# CPU_SCS register map
Vendor: Texas Instruments
Peripheral module from a debugger description file (folder CC26x0R2F).
Registers are 32-bit, read-write, reset 0x0 unless marked. A register's access mark holds for its fields unless they carry their own. Offsets are as the file gives them; lines under a group give offsets from that group; [hi:lo] are bit positions; {n}, {i} and the like mark numbered series; 'fields as' and 'values as' point back to an identical list; <NAME> marks a mode.

## CPU_SCS — Cortex-M's System Control Space (SCS)
0x04 ICTR ro reset 0x1 — Interrupt Control Type Read this register to see the number of interrupt lines that the NVIC supports.
  [2:0] INTLINESNUM — Total number of interrupt lines in groups of 32. 0: 0...32 1: 33...64 2: 65...96 3: 97...128 4: 129...160 5: 161...192 6: 193...224 7: 225...256
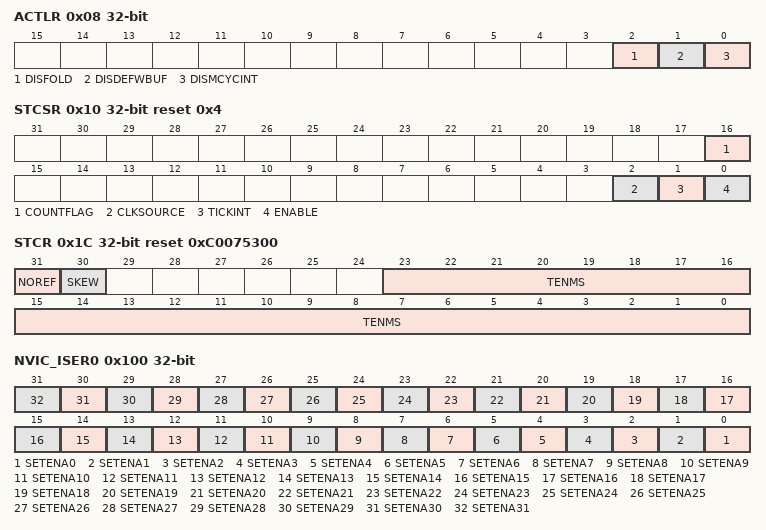
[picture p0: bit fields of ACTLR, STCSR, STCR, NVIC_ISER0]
0x08 ACTLR — Auxiliary Control This register is used to disable certain aspects of functionality within the processor
  [2] DISFOLD — Disables folding of IT instruction.
  [1] DISDEFWBUF — Disables write buffer use during default memory map accesses. This causes all bus faults to be precise bus faults but decreases the performance of the processor because the stores to memory have to complete before the next instruction can be executed.
  [0] DISMCYCINT — Disables interruption of multi-cycle instructions. This increases the interrupt latency of the processor becuase LDM/STM completes before interrupt stacking occurs.
0x10 STCSR access per field reset 0x4 — SysTick Control and Status This register enables the SysTick features and returns status flags related to SysTick.
  [16] COUNTFLAG ro — Returns 1 if timer counted to 0 since last time this was read. Clears on read by application of any part of the SysTick Control and Status Register. If read by the debugger using the DAP, this bit is cleared on read-only if the MasterType bit in the **AHB-AP** Control Register is set to 0. Otherwise, COUNTFLAG is not changed by the debugger read.
  [2] CLKSOURCE ro — Clock source: 0: External reference clock. 1: Core clock External clock is not available in this device. Writes to this field will be ignored.
  [1] TICKINT rw — 0: Counting down to zero does not pend the SysTick handler. Software can use COUNTFLAG to determine if the SysTick handler has ever counted to zero. 1: Counting down to zero pends the SysTick handler.
  [0] ENABLE rw — Enable SysTick counter 0: Counter disabled 1: Counter operates in a multi-shot way. That is, counter loads with the Reload value STRVR.RELOAD and then begins counting down. On reaching 0, it sets COUNTFLAG to 1 and optionally pends the SysTick handler, based on TICKINT. It then loads STRVR.RELOAD again, and begins counting.
0x14 STRVR — SysTick Reload Value This register is used to specify the start value to load into the current value register STCVR.CURRENT when the counter reaches 0. It can be any value between 1 and 0x00FFFFFF. A start value of 0 is possible, but has no effect because the SysTick interrupt and STCSR.COUNTFLAG are activated when counting from 1 to 0.
  [23:0] RELOAD — Value to load into the SysTick Current Value Register STCVR.CURRENT when the counter reaches 0.
0x18 STCVR — SysTick Current Value Read from this register returns the current value of SysTick counter. Writing to this register resets the SysTick counter (as well as STCSR.COUNTFLAG).
  [23:0] CURRENT — Current value at the time the register is accessed. No read-modify-write protection is provided, so change with care. Writing to it with any value clears the register to 0. Clearing this register also clears STCSR.COUNTFLAG.
0x1C STCR ro reset 0xC0075300 — SysTick Calibration Value Used to enable software to scale to any required speed using divide and multiply.
  [31] NOREF — Reads as one. Indicates that no separate reference clock is provided.
  [30] SKEW — Reads as one. The calibration value is not exactly 10ms because of clock frequency. This could affect its suitability as a software real time clock.
  [23:0] TENMS — An optional Reload value to be used for 10ms (100Hz) timing, subject to system clock skew errors. The value read is valid only when core clock is at 48MHz.
0x100 NVIC_ISER0 — Irq 0 to 31 Set Enable This register is used to enable interrupts and determine which interrupts are currently enabled.
  [n] SETENA{n} (n=0..31) — Writing 0 to this bit has no effect, writing 1 to this bit enables the interrupt number {n} (See EVENT:CPUIRQSEL{n}.EV for details). Reading the bit returns its current enable state.
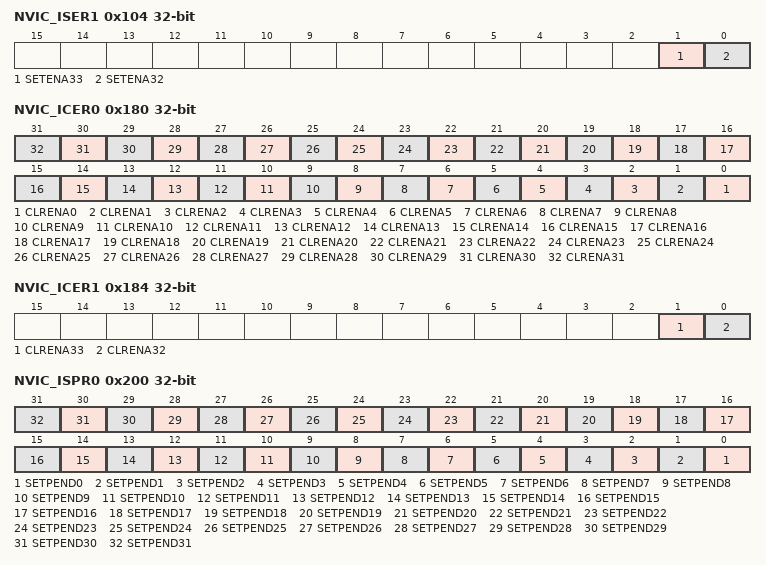
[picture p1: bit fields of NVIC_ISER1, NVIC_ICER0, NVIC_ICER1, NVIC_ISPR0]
0x104 NVIC_ISER1 — Irq 32 to 63 Set Enable This register is used to enable interrupts and determine which interrupts are currently enabled.
  [1] SETENA33 — Writing 0 to this bit has no effect, writing 1 to this bit enables the interrupt number 33 (See EVENT:CPUIRQSEL33.EV for details). Reading the bit returns its current enable state.
  [0] SETENA32 — Writing 0 to this bit has no effect, writing 1 to this bit enables the interrupt number 32 (See EVENT:CPUIRQSEL32.EV for details). Reading the bit returns its current enable state.
0x180 NVIC_ICER0 — Irq 0 to 31 Clear Enable This register is used to disable interrupts and determine which interrupts are currently enabled.
  [n] CLRENA{n} (n=0..31) — Writing 0 to this bit has no effect, writing 1 to this bit disables the interrupt number {n} (See EVENT:CPUIRQSEL{n}.EV for details). Reading the bit returns its current enable state.
0x184 NVIC_ICER1 — Irq 32 to 63 Clear Enable This register is used to disable interrupts and determine which interrupts are currently enabled.
  [1] CLRENA33 — Writing 0 to this bit has no effect, writing 1 to this bit disables the interrupt number 33 (See EVENT:CPUIRQSEL33.EV for details). Reading the bit returns its current enable state.
  [0] CLRENA32 — Writing 0 to this bit has no effect, writing 1 to this bit disables the interrupt number 32 (See EVENT:CPUIRQSEL32.EV for details). Reading the bit returns its current enable state.
0x200 NVIC_ISPR0 — Irq 0 to 31 Set Pending This register is used to force interrupts into the pending state and determine which interrupts are currently pending.
  [n] SETPEND{n} (n=0..31) — Writing 0 to this bit has no effect, writing 1 to this bit pends the interrupt number {n} (See EVENT:CPUIRQSEL{n}.EV for details). Reading the bit returns its current state.
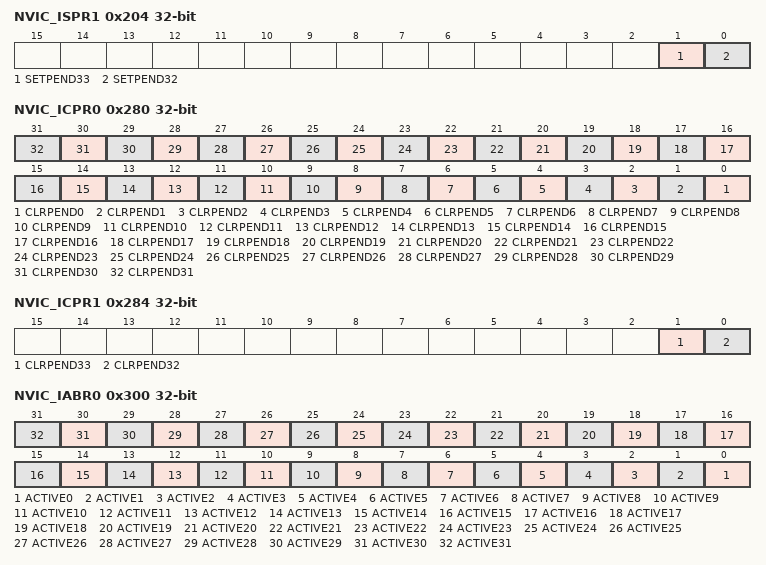
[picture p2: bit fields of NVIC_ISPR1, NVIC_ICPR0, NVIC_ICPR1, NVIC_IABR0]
0x204 NVIC_ISPR1 — Irq 32 to 63 Set Pending This register is used to force interrupts into the pending state and determine which interrupts are currently pending.
  [1] SETPEND33 — Writing 0 to this bit has no effect, writing 1 to this bit pends the interrupt number 33 (See EVENT:CPUIRQSEL33.EV for details). Reading the bit returns its current state.
  [0] SETPEND32 — Writing 0 to this bit has no effect, writing 1 to this bit pends the interrupt number 32 (See EVENT:CPUIRQSEL32.EV for details). Reading the bit returns its current state.
0x280 NVIC_ICPR0 — Irq 0 to 31 Clear Pending This register is used to clear pending interrupts and determine which interrupts are currently pending.
  [n] CLRPEND{n} (n=0..31) — Writing 0 to this bit has no effect, writing 1 to this bit clears the corresponding pending interrupt {n} (See EVENT:CPUIRQSEL{n}.EV for details). Reading the bit returns its current state.
0x284 NVIC_ICPR1 — Irq 32 to 63 Clear Pending This register is used to clear pending interrupts and determine which interrupts are currently pending.
  [1] CLRPEND33 — Writing 0 to this bit has no effect, writing 1 to this bit clears the corresponding pending interrupt 33 (See EVENT:CPUIRQSEL33.EV for details). Reading the bit returns its current state.
  [0] CLRPEND32 — Writing 0 to this bit has no effect, writing 1 to this bit clears the corresponding pending interrupt 32 (See EVENT:CPUIRQSEL32.EV for details). Reading the bit returns its current state.
0x300 NVIC_IABR0 ro — Irq 0 to 31 Active Bit This register is used to determine which interrupts are active. Each flag in the register corresponds to one interrupt.
  [n] ACTIVE{n} (n=0..31) — Reading 0 from this bit implies that interrupt line {n} is not active. Reading 1 from this bit implies that the interrupt line {n} is active (See EVENT:CPUIRQSEL{n}.EV for details).
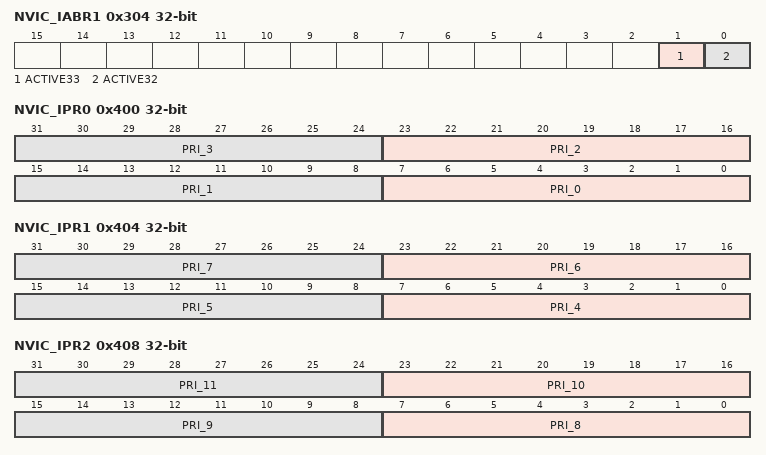
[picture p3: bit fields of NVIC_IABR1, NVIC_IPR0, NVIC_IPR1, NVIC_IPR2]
0x304 NVIC_IABR1 ro — Irq 32 to 63 Active Bit This register is used to determine which interrupts are active. Each flag in the register corresponds to one interrupt.
  [1] ACTIVE33 — Reading 0 from this bit implies that interrupt line 33 is not active. Reading 1 from this bit implies that the interrupt line 33 is active (See EVENT:CPUIRQSEL33.EV for details).
  [0] ACTIVE32 — Reading 0 from this bit implies that interrupt line 32 is not active. Reading 1 from this bit implies that the interrupt line 32 is active (See EVENT:CPUIRQSEL32.EV for details).
0x400 NVIC_IPR0 — Irq 0 to 3 Priority This register is used to assign a priority from 0 to 255 to each of the available interrupts. 0 is the highest priority, and 255 is the lowest. The interpretation of the Interrupt Priority Registers changes based on the setting in AIRCR.PRIGROUP.
  [8n+7:8n] PRI_{n} (n=0..3) — Priority of interrupt {n} (See EVENT:CPUIRQSEL{n}.EV for details).
0x404 NVIC_IPR1 — Irq 4 to 7 Priority This register is used to assign a priority from 0 to 255 to each of the available interrupts. 0 is the highest priority, and 255 is the lowest. The interpretation of the Interrupt Priority Registers changes based on the setting in AIRCR.PRIGROUP.
  [8n-25:8n-32] PRI_{n} (n=4..7) — Priority of interrupt {n} (See EVENT:CPUIRQSEL{n}.EV for details).
0x408 NVIC_IPR2 — Irq 8 to 11 Priority This register is used to assign a priority from 0 to 255 to each of the available interrupts. 0 is the highest priority, and 255 is the lowest. The interpretation of the Interrupt Priority Registers changes based on the setting in AIRCR.PRIGROUP.
  [8n-57:8n-64] PRI_{n} (n=8..11) — Priority of interrupt {n} (See EVENT:CPUIRQSEL{n}.EV for details).
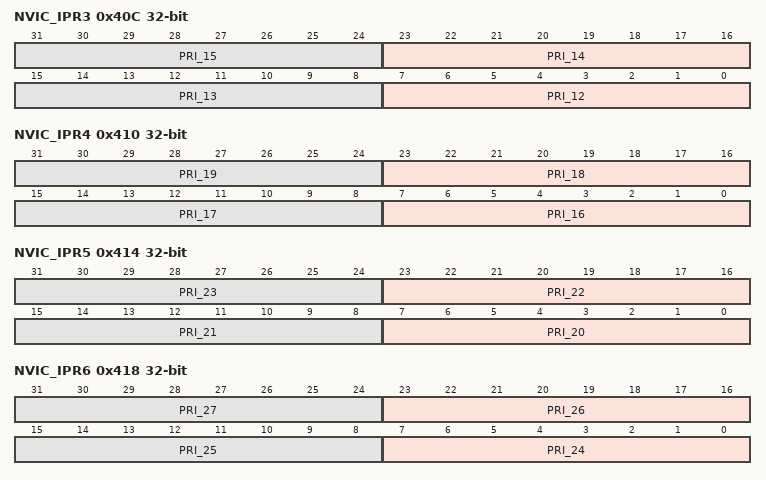
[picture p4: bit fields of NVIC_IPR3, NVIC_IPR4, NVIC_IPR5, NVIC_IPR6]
0x40C NVIC_IPR3 — Irq 12 to 15 Priority This register is used to assign a priority from 0 to 255 to each of the available interrupts. 0 is the highest priority, and 255 is the lowest. The interpretation of the Interrupt Priority Registers changes based on the setting in AIRCR.PRIGROUP.
  [8n-89:8n-96] PRI_{n} (n=12..15) — Priority of interrupt {n} (See EVENT:CPUIRQSEL{n}.EV for details).
0x410 NVIC_IPR4 — Irq 16 to 19 Priority This register is used to assign a priority from 0 to 255 to each of the available interrupts. 0 is the highest priority, and 255 is the lowest. The interpretation of the Interrupt Priority Registers changes based on the setting in AIRCR.PRIGROUP.
  [8n-121:8n-128] PRI_{n} (n=16..19) — Priority of interrupt {n} (See EVENT:CPUIRQSEL{n}.EV for details).
0x414 NVIC_IPR5 — Irq 20 to 23 Priority This register is used to assign a priority from 0 to 255 to each of the available interrupts. 0 is the highest priority, and 255 is the lowest. The interpretation of the Interrupt Priority Registers changes based on the setting in AIRCR.PRIGROUP.
  [8n-153:8n-160] PRI_{n} (n=20..23) — Priority of interrupt {n} (See EVENT:CPUIRQSEL{n}.EV for details).
0x418 NVIC_IPR6 — Irq 24 to 27 Priority This register is used to assign a priority from 0 to 255 to each of the available interrupts. 0 is the highest priority, and 255 is the lowest. The interpretation of the Interrupt Priority Registers changes based on the setting in AIRCR.PRIGROUP.
  [8n-185:8n-192] PRI_{n} (n=24..27) — Priority of interrupt {n} (See EVENT:CPUIRQSEL{n}.EV for details).
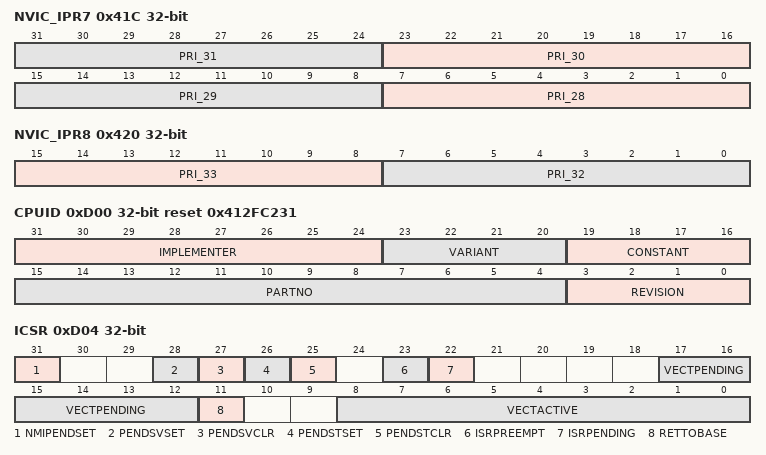
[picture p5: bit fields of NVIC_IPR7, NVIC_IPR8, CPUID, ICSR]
0x41C NVIC_IPR7 — Irq 28 to 31 Priority This register is used to assign a priority from 0 to 255 to each of the available interrupts. 0 is the highest priority, and 255 is the lowest. The interpretation of the Interrupt Priority Registers changes based on the setting in AIRCR.PRIGROUP.
  [8n-217:8n-224] PRI_{n} (n=28..31) — Priority of interrupt {n} (See EVENT:CPUIRQSEL{n}.EV for details).
0x420 NVIC_IPR8 — Irq 32 to 35 Priority This register is used to assign a priority from 0 to 255 to each of the available interrupts. 0 is the highest priority, and 255 is the lowest. The interpretation of the Interrupt Priority Registers changes based on the setting in AIRCR.PRIGROUP.
  [15:8] PRI_33 — Priority of interrupt 33 (See EVENT:CPUIRQSEL33.EV for details).
  [7:0] PRI_32 — Priority of interrupt 32 (See EVENT:CPUIRQSEL32.EV for details).
0xD00 CPUID ro reset 0x412FC231 — CPUID Base This register determines the ID number of the processor core, the version number of the processor core and the implementation details of the processor core.
  [31:24] IMPLEMENTER — Implementor code.
  [23:20] VARIANT — Implementation defined variant number.
  [19:16] CONSTANT — Reads as 0xF
  [15:4] PARTNO — Number of processor within family.
  [3:0] REVISION — Implementation defined revision number.
0xD04 ICSR access per field — Interrupt Control State This register is used to set a pending Non-Maskable Interrupt (NMI), set or clear a pending SVC, set or clear a pending SysTick, check for pending exceptions, check the vector number of the highest priority pended exception, and check the vector number of the active exception.
  [31] NMIPENDSET rw — Set pending NMI bit. Setting this bit pends and activates an NMI. Because NMI is the highest-priority interrupt, it takes effect as soon as it registers. 0: No action 1: Set pending NMI
  [28] PENDSVSET rw — Set pending pendSV bit. 0: No action 1: Set pending PendSV
  [27] PENDSVCLR wo — Clear pending pendSV bit 0: No action 1: Clear pending pendSV
  [26] PENDSTSET rw — Set a pending SysTick bit. 0: No action 1: Set pending SysTick
  [25] PENDSTCLR wo — Clear pending SysTick bit 0: No action 1: Clear pending SysTick
  [23] ISRPREEMPT ro — This field can only be used at debug time. It indicates that a pending interrupt is to be taken in the next running cycle. If DHCSR.C_MASKINTS= 0, the interrupt is serviced. 0: A pending exception is not serviced. 1: A pending exception is serviced on exit from the debug halt state
  [22] ISRPENDING ro — Interrupt pending flag. Excludes NMI and faults. 0x0: Interrupt not pending 0x1: Interrupt pending
  [17:12] VECTPENDING ro — Pending ISR number field. This field contains the interrupt number of the highest priority pending ISR.
  [11] RETTOBASE ro — Indicates whether there are preempted active exceptions: 0: There are preempted active exceptions to execute 1: There are no active exceptions, or the currently-executing exception is the only active exception.
  [8:0] VECTACTIVE ro — Active ISR number field. Reset clears this field.
0xD08 VTOR — Vector Table Offset This register is used to relocated the vector table base address. The vector table base offset determines the offset from the bottom of the memory map. The two most significant bits and the seven least significant bits of the vector table base offset must be 0. The portion of vector table base offset that is allowed to change is TBLOFF.
  [29:7] TBLOFF — Bits 29 down to 7 of the vector table base offset.
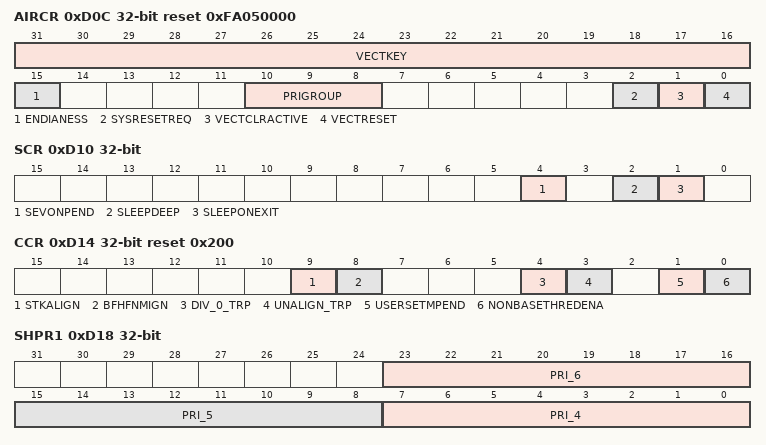
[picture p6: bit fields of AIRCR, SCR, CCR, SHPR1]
0xD0C AIRCR access per field reset 0xFA050000 — Application Interrupt/Reset Control This register is used to determine data endianness, clear all active state information for debug or to recover from a hard failure, execute a system reset, alter the priority grouping position (binary point).
  [31:16] VECTKEY rw — Register key. Writing to this register (AIRCR) requires 0x05FA in VECTKEY. Otherwise the write value is ignored. Read always returns 0xFA05.
  [15] ENDIANESS ro — Data endianness bit
    1=BIG (Big endian); 0=LITTLE (Little endian)
  [10:8] PRIGROUP rw — Interrupt priority grouping field. This field is a binary point position indicator for creating subpriorities for exceptions that share the same pre-emption level. It divides the PRI_n field in the Interrupt Priority Registers (NVIC_IPR0, NVIC_IPR1,..., and NVIC_IPR8) into a pre-emption level and a subpriority level. The binary point is a left-of value. This means that the PRIGROUP value represents a point starting at the left of the Least Significant Bit (LSB). The lowest value might not be 0 depending on the number of bits allocated for priorities, and implementation choices.
  [2] SYSRESETREQ wo — Requests a warm reset. Setting this bit does not prevent Halting Debug from running.
  [1] VECTCLRACTIVE wo — Clears all active state information for active NMI, fault, and interrupts. It is the responsibility of the application to reinitialize the stack. This bit is for returning to a known state during debug. The bit self-clears. IPSR is not cleared by this operation. So, if used by an application, it must only be used at the base level of activation, or within a system handler whose active bit can be set.
  [0] VECTRESET wo — System Reset bit. Resets the system, with the exception of debug components. This bit is reserved for debug use and can be written to 1 only when the core is halted. The bit self-clears. Writing this bit to 1 while core is not halted may result in unpredictable behavior.
0xD10 SCR — System Control This register is used for power-management functions, i.e., signaling to the system when the processor can enter a low power state, controlling how the processor enters and exits low power states.
  [4] SEVONPEND — Send Event on Pending bit: 0: Only enabled interrupts or events can wakeup the processor, disabled interrupts are excluded 1: Enabled events and all interrupts, including disabled interrupts, can wakeup the processor. When an event or interrupt enters pending state, the event signal wakes up the processor from WFE. If the processor is not waiting for an event, the event is registered and affects the next WFE. The processor also wakes up on execution of an SEV instruction.
  [2] SLEEPDEEP — Controls whether the processor uses sleep or deep sleep as its low power mode
    1=DEEPSLEEP; 0=SLEEP
  [1] SLEEPONEXIT — Sleep on exit when returning from Handler mode to Thread mode. Enables interrupt driven applications to avoid returning to empty main application. 0: Do not sleep when returning to thread mode 1: Sleep on ISR exit
0xD14 CCR reset 0x200 — Configuration Control This register is used to enable NMI, HardFault and FAULTMASK to ignore bus fault, trap divide by zero and unaligned accesses, enable user access to the Software Trigger Interrupt Register (STIR), control entry to Thread Mode.
  [9] STKALIGN — Stack alignment bit. 0: Only 4-byte alignment is guaranteed for the SP used prior to the exception on exception entry. 1: On exception entry, the SP used prior to the exception is adjusted to be 8-byte aligned and the context to restore it is saved. The SP is restored on the associated exception return.
  [8] BFHFNMIGN — Enables handlers with priority -1 or -2 to ignore data BusFaults caused by load and store instructions. This applies to the HardFault, NMI, and FAULTMASK escalated handlers: 0: Data BusFaults caused by load and store instructions cause a lock-up 1: Data BusFaults caused by load and store instructions are ignored. Set this bit to 1 only when the handler and its data are in absolutely safe memory. The normal use of this bit is to probe system devices and bridges to detect problems.
  [4] DIV_0_TRP — Enables faulting or halting when the processor executes an SDIV or UDIV instruction with a divisor of 0: 0: Do not trap divide by 0. In this mode, a divide by zero returns a quotient of 0. 1: Trap divide by 0. The relevant Usage Fault Status Register bit is CFSR.DIVBYZERO.
  [3] UNALIGN_TRP — Enables unaligned access traps: 0: Do not trap unaligned halfword and word accesses 1: Trap unaligned halfword and word accesses. The relevant Usage Fault Status Register bit is CFSR.UNALIGNED. If this bit is set to 1, an unaligned access generates a UsageFault. Unaligned LDM, STM, LDRD, and STRD instructions always fault regardless of the value in UNALIGN_TRP.
  [1] USERSETMPEND — Enables unprivileged software access to STIR: 0: User code is not allowed to write to the Software Trigger Interrupt register (STIR). 1: User code can write the Software Trigger Interrupt register (STIR) to trigger (pend) a Main exception, which is associated with the Main stack pointer.
  [0] NONBASETHREDENA — Indicates how the processor enters Thread mode: 0: Processor can enter Thread mode only when no exception is active. 1: Processor can enter Thread mode from any level using the appropriate return value (EXC_RETURN). Exception returns occur when one of the following instructions loads a value of 0xFXXXXXXX into the PC while in Handler mode: - POP/LDM which includes loading the PC. - LDR with PC as a destination. - BX with any register. The value written to the PC is intercepted and is referred to as the EXC_RETURN value.
0xD18 SHPR1 — System Handlers 4-7 Priority This register is used to prioritize the following system handlers: Memory manage, Bus fault, and Usage fault. System Handlers are a special class of exception handler that can have their priority set to any of the priority levels. Most can be masked on (enabled) or off (disabled). When disabled, the fault is always treated as a Hard Fault.
  [23:16] PRI_6 — Priority of system handler 6. UsageFault
  [15:8] PRI_5 — Priority of system handler 5: BusFault
  [7:0] PRI_4 — Priority of system handler 4: MemManage
0xD1C SHPR2 — System Handlers 8-11 Priority This register is used to prioritize the SVC handler. System Handlers are a special class of exception handler that can have their priority set to any of the priority levels. Most can be masked on (enabled) or off (disabled). When disabled, the fault is always treated as a Hard Fault.
  [31:24] PRI_11 — Priority of system handler 11. SVCall
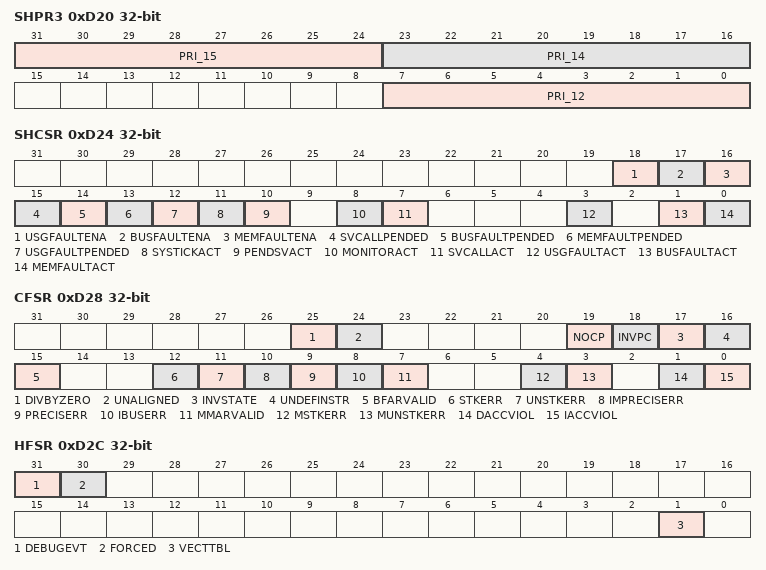
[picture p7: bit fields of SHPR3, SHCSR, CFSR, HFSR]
0xD20 SHPR3 — System Handlers 12-15 Priority This register is used to prioritize the following system handlers: SysTick, PendSV and Debug Monitor. System Handlers are a special class of exception handler that can have their priority set to any of the priority levels. Most can be masked on (enabled) or off (disabled). When disabled, the fault is always treated as a Hard Fault.
  [31:24] PRI_15 — Priority of system handler 15. SysTick exception
  [23:16] PRI_14 — Priority of system handler 14. Pend SV
  [7:0] PRI_12 — Priority of system handler 12. Debug Monitor
0xD24 SHCSR access per field — System Handler Control and State This register is used to enable or disable the system handlers, determine the pending status of bus fault, mem manage fault, and SVC, determine the active status of the system handlers. If a fault condition occurs while its fault handler is disabled, the fault escalates to a Hard Fault.
  [18] USGFAULTENA rw — Usage fault system handler enable
    1=EN (Exception enabled); 0=DIS (Exception disabled)
  [17] BUSFAULTENA rw — Bus fault system handler enable
    1=EN (Exception enabled); 0=DIS (Exception disabled)
  [16] MEMFAULTENA rw — MemManage fault system handler enable
    1=EN (Exception enabled); 0=DIS (Exception disabled)
  [15] SVCALLPENDED ro — SVCall pending
    1=PENDING (Exception is pending.); 0=NOTPENDING (Exception is not active)
  [14] BUSFAULTPENDED ro — BusFault pending
    values as SVCALLPENDED
  [13] MEMFAULTPENDED ro — MemManage exception pending
    values as SVCALLPENDED
  [12] USGFAULTPENDED ro — Usage fault pending
    values as SVCALLPENDED
  [11] SYSTICKACT ro — SysTick active flag. 0x0: Not active 0x1: Active
    1=ACTIVE (Exception is active); 0=NOTACTIVE (Exception is not active)
  [10] PENDSVACT ro — PendSV active 0x0: Not active 0x1: Active
  [8] MONITORACT ro — Debug monitor active
    values as SYSTICKACT
  [7] SVCALLACT ro — SVCall active
    values as SYSTICKACT
  [3] USGFAULTACT ro — UsageFault exception active
    values as SYSTICKACT
  [1] BUSFAULTACT ro — BusFault exception active
    values as SYSTICKACT
  [0] MEMFAULTACT ro — MemManage exception active
    values as SYSTICKACT
0xD28 CFSR — Configurable Fault Status This register is used to obtain information about local faults. These registers include three subsections: The first byte is Memory Manage Fault Status Register (MMFSR). The second byte is Bus Fault Status Register (BFSR). The higher half-word is Usage Fault Status Register (UFSR). The flags in these registers indicate the causes of local faults. Multiple flags can be set if more than one fault occurs. These register are read/write-clear. This means that they can be read normally, but writing a 1 to any bit clears that bit. The CFSR is byte accessible. CFSR or its subregisters can be accessed as follows: The following accesses are possible to the CFSR register: - access the complete register with a word access to 0xE000ED28. - access the MMFSR with a byte access to 0xE000ED28 - access the MMFSR and BFSR with a halfword access to 0xE000ED28 - access the BFSR with a byte access to 0xE000ED29 - access the UFSR with a halfword access to 0xE000ED2A.
  [25] DIVBYZERO — When CCR.DIV_0_TRP (see Configuration Control Register on page 8-26) is enabled and an SDIV or UDIV instruction is used with a divisor of 0, this fault occurs The instruction is executed and the return PC points to it. If CCR.DIV_0_TRP is not set, then the divide returns a quotient of 0.
  [24] UNALIGNED — When CCR.UNALIGN_TRP is enabled, and there is an attempt to make an unaligned memory access, then this fault occurs. Unaligned LDM/STM/LDRD/STRD instructions always fault irrespective of the setting of CCR.UNALIGN_TRP.
  [19] NOCP — Attempt to use a coprocessor instruction. The processor does not support coprocessor instructions.
  [18] INVPC — Attempt to load EXC_RETURN into PC illegally. Invalid instruction, invalid context, invalid value. The return PC points to the instruction that tried to set the PC.
  [17] INVSTATE — Indicates an attempt to execute in an invalid EPSR state (e.g. after a BX type instruction has changed state). This includes state change after entry to or return from exception, as well as from inter-working instructions. Return PC points to faulting instruction, with the invalid state.
  [16] UNDEFINSTR — This bit is set when the processor attempts to execute an undefined instruction. This is an instruction that the processor cannot decode. The return PC points to the undefined instruction.
  [15] BFARVALID — This bit is set if the Bus Fault Address Register (BFAR) contains a valid address. This is true after a bus fault where the address is known. Other faults can clear this bit, such as a Mem Manage fault occurring later. If a Bus fault occurs that is escalated to a Hard Fault because of priority, the Hard Fault handler must clear this bit. This prevents problems if returning to a stacked active Bus fault handler whose BFAR value has been overwritten.
  [12] STKERR — Stacking from exception has caused one or more bus faults. The SP is still adjusted and the values in the context area on the stack might be incorrect. BFAR is not written.
  [11] UNSTKERR — Unstack from exception return has caused one or more bus faults. This is chained to the handler, so that the original return stack is still present. SP is not adjusted from failing return and new save is not performed. BFAR is not written.
  [10] IMPRECISERR — Imprecise data bus error. It is a BusFault, but the Return PC is not related to the causing instruction. This is not a synchronous fault. So, if detected when the priority of the current activation is higher than the Bus Fault, it only pends. Bus fault activates when returning to a lower priority activation. If a precise fault occurs before returning to a lower priority exception, the handler detects both IMPRECISERR set and one of the precise fault status bits set at the same time. BFAR is not written.
  [9] PRECISERR — Precise data bus error return.
  [8] IBUSERR — Instruction bus error flag. This flag is set by a prefetch error. The fault stops on the instruction, so if the error occurs under a branch shadow, no fault occurs. BFAR is not written.
  [7] MMARVALID — Memory Manage Address Register (MMFAR) address valid flag. A later-arriving fault, such as a bus fault, can clear a memory manage fault.. If a MemManage fault occurs that is escalated to a Hard Fault because of priority, the Hard Fault handler must clear this bit. This prevents problems on return to a stacked active MemManage handler whose MMFAR value has been overwritten.
  [4] MSTKERR — Stacking from exception has caused one or more access violations. The SP is still adjusted and the values in the context area on the stack might be incorrect. MMFAR is not written.
  [3] MUNSTKERR — Unstack from exception return has caused one or more access violations. This is chained to the handler, so that the original return stack is still present. SP is not adjusted from failing return and new save is not performed. MMFAR is not written.
  [1] DACCVIOL — Data access violation flag. Attempting to load or store at a location that does not permit the operation sets this flag. The return PC points to the faulting instruction. This error loads MMFAR with the address of the attempted access.
  [0] IACCVIOL — Instruction access violation flag. Attempting to fetch an instruction from a location that does not permit execution sets this flag. This occurs on any access to an XN region, even when the MPU is disabled or not present. The return PC points to the faulting instruction. MMFAR is not written.
0xD2C HFSR — Hard Fault Status This register is used to obtain information about events that activate the Hard Fault handler. This register is a write-clear register. This means that writing a 1 to a bit clears that bit.
  [31] DEBUGEVT — This bit is set if there is a fault related to debug. This is only possible when halting debug is not enabled. For monitor enabled debug, it only happens for BKPT when the current priority is higher than the monitor. When both halting and monitor debug are disabled, it only happens for debug events that are not ignored (minimally, BKPT). The Debug Fault Status Register is updated.
  [30] FORCED — Hard Fault activated because a Configurable Fault was received and cannot activate because of priority or because the Configurable Fault is disabled. The Hard Fault handler then has to read the other fault status registers to determine cause.
  [1] VECTTBL — This bit is set if there is a fault because of vector table read on exception processing (Bus Fault). This case is always a Hard Fault. The return PC points to the pre-empted instruction.
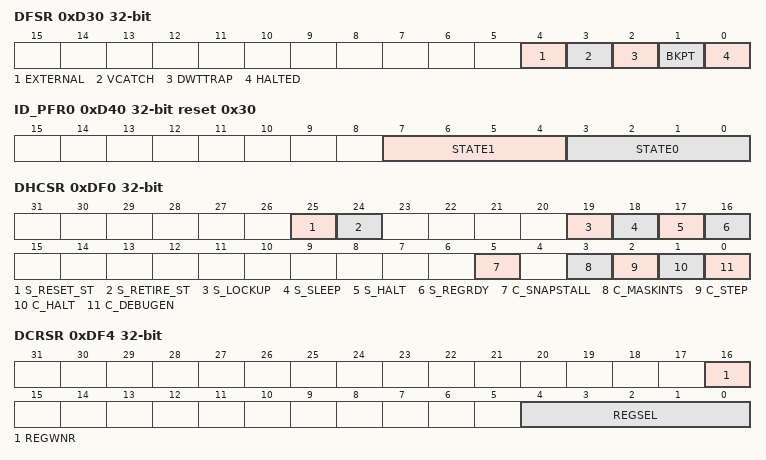
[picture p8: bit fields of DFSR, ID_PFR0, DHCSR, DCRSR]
0xD30 DFSR — Debug Fault Status This register is used to monitor external debug requests, vector catches, data watchpoint match, BKPT instruction execution, halt requests. Multiple flags in the Debug Fault Status Register can be set when multiple fault conditions occur. The register is read/write clear. This means that it can be read normally. Writing a 1 to a bit clears that bit. Note that these bits are not set unless the event is caught. This means that it causes a stop of some sort. If halting debug is enabled, these events stop the processor into debug. If debug is disabled and the debug monitor is enabled, then this becomes a debug monitor handler call, if priority permits. If debug and the monitor are both disabled, some of these events are Hard Faults, and some are ignored.
  [4] EXTERNAL — External debug request flag. The processor stops on next instruction boundary. 0x0: External debug request signal not asserted 0x1: External debug request signal asserted
  [3] VCATCH — Vector catch flag. When this flag is set, a flag in one of the local fault status registers is also set to indicate the type of fault. 0x0: No vector catch occurred 0x1: Vector catch occurred
  [2] DWTTRAP — Data Watchpoint and Trace (DWT) flag. The processor stops at the current instruction or at the next instruction. 0x0: No DWT match 0x1: DWT match
  [1] BKPT — BKPT flag. The BKPT flag is set by a BKPT instruction in flash patch code, and also by normal code. Return PC points to breakpoint containing instruction. 0x0: No BKPT instruction execution 0x1: BKPT instruction execution
  [0] HALTED — Halt request flag. The processor is halted on the next instruction. 0x0: No halt request 0x1: Halt requested by NVIC, including step
0xD34 MMFAR — Mem Manage Fault Address This register is used to read the address of the location that caused a Memory Manage Fault.
  [31:0] ADDRESS — Mem Manage fault address field. This field is the data address of a faulted load or store attempt. When an unaligned access faults, the address is the actual address that faulted. Because an access can be split into multiple parts, each aligned, this address can be any offset in the range of the requested size. Flags CFSR.IACCVIOL, CFSR.DACCVIOL ,CFSR.MUNSTKERR and CFSR.MSTKERR in combination with CFSR.MMARVALIDindicate the cause of the fault.
0xD38 BFAR — Bus Fault Address This register is used to read the address of the location that generated a Bus Fault.
  [31:0] ADDRESS — Bus fault address field. This field is the data address of a faulted load or store attempt. When an unaligned access faults, the address is the address requested by the instruction, even if that is not the address that faulted. Flags CFSR.IBUSERR, CFSR.PRECISERR, CFSR.IMPRECISERR, CFSR.UNSTKERR and CFSR.STKERR in combination with CFSR.BFARVALID indicate the cause of the fault.
0xD3C AFSR — Auxiliary Fault Status This register is used to determine additional system fault information to software. Single-cycle high level on an auxiliary faults is latched as one. The bit can only be cleared by writing a one to the corresponding bit. Auxiliary fault inputs to the CPU are tied to 0.
  [31:0] IMPDEF — Implementation defined. The bits map directly onto the signal assignment to the auxiliary fault inputs. Tied to 0
0xD40 ID_PFR0 ro reset 0x30 — Processor Feature 0
  [7:4] STATE1 — State1 (T-bit == 1) 0x0: N/A 0x1: N/A 0x2: Thumb-2 encoding with the 16-bit basic instructions plus 32-bit Buncond/BL but no other 32-bit basic instructions (Note non-basic 32-bit instructions can be added using the appropriate instruction attribute, but other 32-bit basic instructions cannot.) 0x3: Thumb-2 encoding with all Thumb-2 basic instructions
  [3:0] STATE0 — State0 (T-bit == 0) 0x0: No ARM encoding 0x1: N/A
0xD44 ID_PFR1 ro reset 0x200 — Processor Feature 1
  [11:8] MICROCONTROLLER_PROGRAMMERS_MODEL — Microcontroller programmer's model 0x0: Not supported 0x2: Two-stack support
0xD48 ID_DFR0 ro reset 0x100000 — Debug Feature 0 This register provides a high level view of the debug system. Further details are provided in the debug infrastructure itself.
  [23:20] MICROCONTROLLER_DEBUG_MODEL — Microcontroller Debug Model - memory mapped 0x0: Not supported 0x1: Microcontroller debug v1 (ITMv1 and DWTv1)
0xD4C ID_AFR0 ro — Auxiliary Feature 0 This register provides some freedom for implementation defined features to be registered. Not used in Cortex-M.
0xD50 ID_MMFR0 ro reset 0x100030 — Memory Model Feature 0 General information on the memory model and memory management support.
0xD54 ID_MMFR1 ro — Memory Model Feature 1 General information on the memory model and memory management support.
0xD58 ID_MMFR2 ro reset 0x1000000 — Memory Model Feature 2 General information on the memory model and memory management support.
  [24] WAIT_FOR_INTERRUPT_STALLING — wait for interrupt stalling 0x0: Not supported 0x1: Wait for interrupt supported
0xD5C ID_MMFR3 ro — Memory Model Feature 3 General information on the memory model and memory management support.
0xD60 ID_ISAR0 ro reset 0x1101110 — ISA Feature 0 Information on the instruction set attributes register
0xD64 ID_ISAR1 ro reset 0x2111000 — ISA Feature 1 Information on the instruction set attributes register
0xD68 ID_ISAR2 ro reset 0x21112231 — ISA Feature 2 Information on the instruction set attributes register
0xD6C ID_ISAR3 ro reset 0x1111110 — ISA Feature 3 Information on the instruction set attributes register
0xD70 ID_ISAR4 ro reset 0x1310132 — ISA Feature 4 Information on the instruction set attributes register
0xD88 CPACR — Coprocessor Access Control This register specifies the access privileges for coprocessors.
0xDF0 DHCSR access per field — Debug Halting Control and Status The purpose of this register is to provide status information about the state of the processor, enable core debug, halt and step the processor. For writes, 0xA05F must be written to higher half-word of this register, otherwise the write operation is ignored and no bits are written into the register. If not enabled for Halting mode, C_DEBUGEN = 1, all other fields are disabled. This register is not reset on a core reset. It is reset by a power-on reset. However, C_HALT always clears on a core reset. To halt on a reset, the following bits must be enabled: DEMCR.VC_CORERESET and C_DEBUGEN. Note that writes to this register in any size other than word are unpredictable. It is acceptable to read in any size, and it can be used to avoid or intentionally change a sticky bit. Behavior of the system when writing to this register while CPU is halted (i.e. C_DEBUGEN = 1 and S_HALT= 1): C_HALT=0, C_STEP=0, C_MASKINTS=0 Exit Debug state and start instruction execution. Exceptions activate according to the exception configuration rules. C_HALT=0, C_STEP=0, C_MASKINTS=1 Exit Debug state and start instruction execution. PendSV, SysTick and external configurable interrupts are disabled, otherwise exceptions activate according to standard configuration rules. C_HALT=0, C_STEP=1, C_MASKINTS=0 Exit Debug state, step an instruction and halt. Exceptions activate according to the exception configuration rules. C_HALT=0, C_STEP=1, C_MASKINTS=1 Exit Debug state, step an instruction and halt. PendSV, SysTick and external configurable interrupts are disabled, otherwise exceptions activate according to standard configuration rules. C_HALT=1, C_STEP=x, C_MASKINTS=x Remain in Debug state
  [25] S_RESET_ST rw — Indicates that the core has been reset, or is now being reset, since the last time this bit was read. This a sticky bit that clears on read. So, reading twice and getting 1 then 0 means it was reset in the past. Reading twice and getting 1 both times means that it is being reset now (held in reset still). When writing to this register, 0 must be written this bit-field, otherwise the write operation is ignored and no bits are written into the register.
  [24] S_RETIRE_ST rw — Indicates that an instruction has completed since last read. This is a sticky bit that clears on read. This determines if the core is stalled on a load/store or fetch. When writing to this register, 0 must be written this bit-field, otherwise the write operation is ignored and no bits are written into the register.
  [19] S_LOCKUP rw — Reads as one if the core is running (not halted) and a lockup condition is present. When writing to this register, 1 must be written this bit-field, otherwise the write operation is ignored and no bits are written into the register.
  [18] S_SLEEP rw — Indicates that the core is sleeping (WFI, WFE, or **SLEEP-ON-EXIT**). Must use C_HALT to gain control or wait for interrupt to wake-up. When writing to this register, 1 must be written this bit-field, otherwise the write operation is ignored and no bits are written into the register.
  [17] S_HALT rw — The core is in debug state when this bit is set. When writing to this register, 1 must be written this bit-field, otherwise the write operation is ignored and no bits are written into the register.
  [16] S_REGRDY rw — Register Read/Write on the Debug Core Register Selector register is available. Last transfer is complete. When writing to this register, 1 must be written this bit-field, otherwise the write operation is ignored and no bits are written into the register.
  [5] C_SNAPSTALL rw — If the core is stalled on a load/store operation the stall ceases and the instruction is forced to complete. This enables Halting debug to gain control of the core. It can only be set if: C_DEBUGEN = 1 and C_HALT = 1. The core reads S_RETIRE_ST as 0. This indicates that no instruction has advanced. This prevents misuse. The bus state is Unpredictable when this is used. S_RETIRE_ST can detect core stalls on load/store operations.
  [3] C_MASKINTS rw — Mask interrupts when stepping or running in halted debug. This masking does not affect NMI, fault exceptions and SVC caused by execution of the instructions. This bit must only be modified when the processor is halted (S_HALT == 1). C_MASKINTS must be set or cleared before halt is released (i.e., the writes to set or clear C_MASKINTS and to set or clear C_HALT must be separate). Modifying C_MASKINTS while the system is running with halting debug support enabled (C_DEBUGEN = 1, S_HALT = 0) may cause unpredictable behavior.
  [2] C_STEP rw — Steps the core in halted debug. When C_DEBUGEN = 0, this bit has no effect. Must only be modified when the processor is halted (S_HALT == 1). Modifying C_STEP while the system is running with halting debug support enabled (C_DEBUGEN = 1, S_HALT = 0) may cause unpredictable behavior.
  [1] C_HALT rw — Halts the core. This bit is set automatically when the core Halts. For example Breakpoint. This bit clears on core reset.
  [0] C_DEBUGEN rw — Enables debug. This can only be written by AHB-AP and not by the core. It is ignored when written by the core, which cannot set or clear it. The core must write a 1 to it when writing C_HALT to halt itself. The values of C_HALT, C_STEP and C_MASKINTS are ignored by hardware when C_DEBUGEN = 0. The read values for C_HALT, C_STEP and C_MASKINTS fields will be unknown to software when C_DEBUGEN = 0.
0xDF4 DCRSR wo — Deubg Core Register Selector The purpose of this register is to select the processor register to transfer data to or from. This write-only register generates a handshake to the core to transfer data to or from Debug Core Register Data Register and the selected register. Until this core transaction is complete, DHCSR.S_REGRDY is 0. Note that writes to this register in any size but word are Unpredictable. Note that PSR registers are fully accessible this way, whereas some read as 0 when using MRS instructions. Note that all bits can be written, but some combinations cause a fault when execution is resumed.
  [16] REGWNR — 1: Write 0: Read
  [4:0] REGSEL — Register select 0x00: R0 0x01: R1 0x02: R2 0x03: R3 0x04: R4 0x05: R5 0x06: R6 0x07: R7 0x08: R8 0x09: R9 0x0A: R10 0x0B: R11 0x0C: R12 0x0D: Current SP 0x0E: LR 0x0F: DebugReturnAddress 0x10: XPSR/flags, execution state information, and exception number 0x11: MSP (Main SP) 0x12: PSP (Process SP) 0x14: CONTROL<<24 | FAULTMASK<<16 | BASEPRI<<8 | PRIMASK
0xDF8 DCRDR — Debug Core Register Data
  [31:0] DCRDR — This register holds data for reading and writing registers to and from the processor. This is the data value written to the register selected by DCRSR. When the processor receives a request from DCRSR, this register is read or written by the processor using a normal load-store unit operation. If core register transfers are not being performed, software-based debug monitors can use this register for communication in non-halting debug. This enables flags and bits to acknowledge state and indicate if commands have been accepted to, replied to, or accepted and replied to.
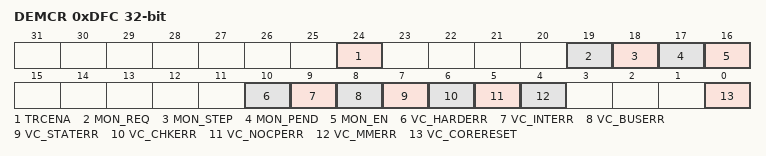
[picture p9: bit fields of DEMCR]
0xDFC DEMCR — Debug Exception and Monitor Control The purpose of this register is vector catching and debug monitor control. This register manages exception behavior under debug. Vector catching is only available to halting debug. The upper halfword is for monitor controls and the lower halfword is for halting exception support. This register is not reset on a system reset. This register is reset by a power-on reset. The fields MON_EN, MON_PEND, MON_STEP and MON_REQ are always cleared on a core reset. The debug monitor is enabled by software in the reset handler or later, or by the **AHB-AP** port. Vector catching is semi-synchronous. When a matching event is seen, a Halt is requested. Because the processor can only halt on an instruction boundary, it must wait until the next instruction boundary. As a result, it stops on the first instruction of the exception handler. However, two special cases exist when a vector catch has triggered: 1. If a fault is taken during a vector read or stack push error the halt occurs on the corresponding fault handler for the vector error or stack push. 2. If a late arriving interrupt detected during a vector read or stack push error it is not taken. That is, an implementation that supports the late arrival optimization must suppress it in this case.
  [24] TRCENA — This bit must be set to 1 to enable use of the trace and debug blocks: DWT, ITM, ETM and TPIU. This enables control of power usage unless tracing is required. The application can enable this, for ITM use, or use by a debugger.
  [19] MON_REQ — This enables the monitor to identify how it wakes up. This bit clears on a Core Reset. 0x0: Woken up by debug exception. 0x1: Woken up by MON_PEND
  [18] MON_STEP — When MON_EN = 1, this steps the core. When MON_EN = 0, this bit is ignored. This is the equivalent to DHCSR.C_STEP. Interrupts are only stepped according to the priority of the monitor and settings of PRIMASK, FAULTMASK, or BASEPRI.
  [17] MON_PEND — Pend the monitor to activate when priority permits. This can wake up the monitor through the AHB-AP port. It is the equivalent to DHCSR.C_HALT for Monitor debug. This register does not reset on a system reset. It is only reset by a power-on reset. Software in the reset handler or later, or by the DAP must enable the debug monitor.
  [16] MON_EN — Enable the debug monitor. When enabled, the System handler priority register controls its priority level. If disabled, then all debug events go to Hard fault. DHCSR.C_DEBUGEN overrides this bit. Vector catching is semi-synchronous. When a matching event is seen, a Halt is requested. Because the processor can only halt on an instruction boundary, it must wait until the next instruction boundary. As a result, it stops on the first instruction of the exception handler. However, two special cases exist when a vector catch has triggered: 1. If a fault is taken during vectoring, vector read or stack push error, the halt occurs on the corresponding fault handler, for the vector error or stack push. 2. If a late arriving interrupt comes in during vectoring, it is not taken. That is, an implementation that supports the late arrival optimization must suppress it in this case.
  [10] VC_HARDERR — Debug trap on Hard Fault. Ignored when DHCSR.C_DEBUGEN is cleared.
  [9] VC_INTERR — Debug trap on a fault occurring during an exception entry or return sequence. Ignored when DHCSR.C_DEBUGEN is cleared.
  [8] VC_BUSERR — Debug Trap on normal Bus error. Ignored when DHCSR.C_DEBUGEN is cleared.
  [7] VC_STATERR — Debug trap on Usage Fault state errors. Ignored when DHCSR.C_DEBUGEN is cleared.
  [6] VC_CHKERR — Debug trap on Usage Fault enabled checking errors. Ignored when DHCSR.C_DEBUGEN is cleared.
  [5] VC_NOCPERR — Debug trap on a UsageFault access to a Coprocessor. Ignored when DHCSR.C_DEBUGEN is cleared.
  [4] VC_MMERR — Debug trap on Memory Management faults. Ignored when DHCSR.C_DEBUGEN is cleared.
  [0] VC_CORERESET — Reset Vector Catch. Halt running system if Core reset occurs. Ignored when DHCSR.C_DEBUGEN is cleared.
0xF00 STIR wo — Software Trigger Interrupt
  [8:0] INTID — Interrupt ID field. Writing a value to this bit-field is the same as manually pending an interrupt by setting the corresponding interrupt bit in an Interrupt Set Pending Register in NVIC_ISPR0 or NVIC_ISPR1.
